# ATSAME54N20A register map
Vendor: Microchip Technology; Series: SAME54; File version: 0
CPU: CM4 r0p1, little endian, MPU, FPU, 3 interrupt priority bits, 137 interrupts
Registers are 32-bit, read-write, reset 0x0 unless marked. A register's access mark holds for its fields unless they carry their own. Offsets are from the block's base; [hi:lo] are bit positions; lines under a group give offsets from that group; {n}, {i} and the like mark numbered series; 'fields as' and 'values as' point back to an identical list.

## SERCOM0 — Serial Communication Interface
Base 0x40003000; register names take the prefix SERCOM_
Same registers: SERCOM1 0x40003400, SERCOM2 0x41012000, SERCOM3 0x41014000, SERCOM4 0x43000000, SERCOM5 0x43000400, SERCOM6 0x43000800, SERCOM7 0x43000C00
0x00 I2CM group — I2C Master Mode
  0x00 CTRLA — I2CM Control A
    [30] LOWTOUTEN — SCL Low Timeout Enable
    [29:28] INACTOUT — Inactive Time-Out
      0=DISABLE (Disabled); 1=55US (5-6 SCL Time-Out(50-60us)); 2=105US (10-11 SCL Time-Out(100-110us)); 3=205US (20-21 SCL Time-Out(200-210us))
    [27] SCLSM — SCL Clock Stretch Mode
    [25:24] SPEED — Transfer Speed
      0=STANDARD_AND_FAST_MODE (Standard Mode(Sm) Upto 100kHz and Fast Mode(Fm) Upto 400kHz); 1=FASTPLUS_MODE (Fast-mode Plus Upto 1MHz); 2=HIGH_SPEED_MODE (High-speed mode Upto 3.4MHz)
    [23] SEXTTOEN — Slave SCL Low Extend Timeout
    [22] MEXTTOEN — Master SCL Low Extend Timeout
    [21:20] SDAHOLD — SDA Hold Time
      0=DISABLE (Disabled); 1=75NS (50-100ns hold time); 2=450NS (300-600ns hold time); 3=600NS (400-800ns hold time)
    [16] PINOUT — Pin Usage
    [7] RUNSTDBY — Run in Standby
    [4:2] MODE — Operating Mode
      0=USART_EXT_CLK (USART with external clock); 1=USART_INT_CLK (USART with internal clock); 2=SPI_SLAVE (SPI in slave operation); 3=SPI_MASTER (SPI in master operation); 4=I2C_SLAVE (I2C slave operation); 5=I2C_MASTER (I2C master operation)
    [1] ENABLE
    [0] SWRST — Software Reset
  0x04 CTRLB — I2CM Control B
    [18] ACKACT — Acknowledge Action
    [17:16] CMD — Command
    [9] QCEN — Quick Command Enable
    [8] SMEN — Smart Mode Enable
  0x08 CTRLC — I2CM Control C
    [24] DATA32B — Data 32 Bit
      0=DATA_TRANS_8BIT (Data transaction from/to DATA register are 8-bit); 1=DATA_TRANS_32BIT (Data transaction from/to DATA register are 32-bit)
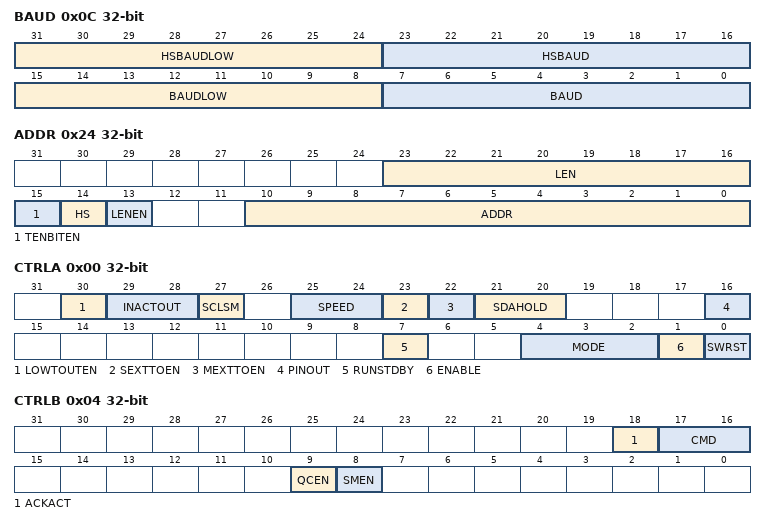
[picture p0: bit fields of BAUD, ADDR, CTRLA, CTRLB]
  0x0C BAUD — I2CM Baud Rate
    [31:24] HSBAUDLOW — High Speed Baud Rate Value Low
    [23:16] HSBAUD — High Speed Baud Rate Value
    [15:8] BAUDLOW — Baud Rate Value Low
    [7:0] BAUD — Baud Rate Value
  0x14 INTENCLR 8-bit write-1-clears — I2CM Interrupt Enable Clear
    [7] ERROR — Combined Error Interrupt Disable
    [1] SB — Slave On Bus Interrupt Disable
    [0] MB — Master On Bus Interrupt Disable
  0x16 INTENSET 8-bit write-1-sets — I2CM Interrupt Enable Set
    [7] ERROR — Combined Error Interrupt Enable
    [1] SB — Slave On Bus Interrupt Enable
    [0] MB — Master On Bus Interrupt Enable
  0x18 INTFLAG 8-bit write-1-clears — I2CM Interrupt Flag Status and Clear
    [7] ERROR — Combined Error Interrupt
    [1] SB — Slave On Bus Interrupt
    [0] MB — Master On Bus Interrupt
  0x1A STATUS 16-bit — I2CM Status
    [10] LENERR — Length Error
    [9] SEXTTOUT — Slave SCL Low Extend Timeout
    [8] MEXTTOUT — Master SCL Low Extend Timeout
    [7] CLKHOLD — Clock Hold
    [6] LOWTOUT — SCL Low Timeout
    [5:4] BUSSTATE
      0=UNKNOWN (The Bus state is unknown to the I2C Host); 1=IDLE (The Bus state is waiting for a transaction to be initialized); 2=OWNER (The I2C Host is the current owner of the bus); 3=BUSY (Some other I2C Host owns the bus)
    [2] RXNACK — Received Not Acknowledge
    [1] ARBLOST — Arbitration Lost
    [0] BUSERR — Bus Error
  0x1C SYNCBUSY ro — I2CM Synchronization Busy
    [2] SYSOP — System Operation Synchronization Busy
    [1] ENABLE — SERCOM Enable Synchronization Busy
    [0] SWRST — Software Reset Synchronization Busy
  0x24 ADDR — I2CM Address
    [23:16] LEN — Length
    [15] TENBITEN — Ten Bit Addressing Enable
    [14] HS — High Speed Mode
    [13] LENEN — Length Enable
    [10:0] ADDR — Address Value
  0x28 DATA — I2CM Data
    [31:0] DATA — Data Value
  0x30 DBGCTRL 8-bit — I2CM Debug Control
    [0] DBGSTOP — Debug Mode
0x00 I2CS group (alternate view of I2CM) — I2C Slave Mode
  0x00 CTRLA — I2CS Control A
    [30] LOWTOUTEN — SCL Low Timeout Enable
    [27] SCLSM — SCL Clock Stretch Mode
    [25:24] SPEED — Transfer Speed
      values as I2CM.CTRLA.SPEED
    [23] SEXTTOEN — Slave SCL Low Extend Timeout
    [21:20] SDAHOLD — SDA Hold Time
      values as I2CM.CTRLA.SDAHOLD
    [16] PINOUT — Pin Usage
    [7] RUNSTDBY — Run during Standby
    [4:2] MODE — Operating Mode
      values as I2CM.CTRLA.MODE
    [1] ENABLE
    [0] SWRST — Software Reset
  0x04 CTRLB — I2CS Control B
    [18] ACKACT — Acknowledge Action
    [17:16] CMD — Command
    [15:14] AMODE — Address Mode
      0=MASK (I2C Address mask); 1=2_ADDRESSES (Two unique Addressess); 2=RANGE (Address Range)
    [10] AACKEN — Automatic Address Acknowledge
    [9] GCMD — PMBus Group Command
    [8] SMEN — Smart Mode Enable
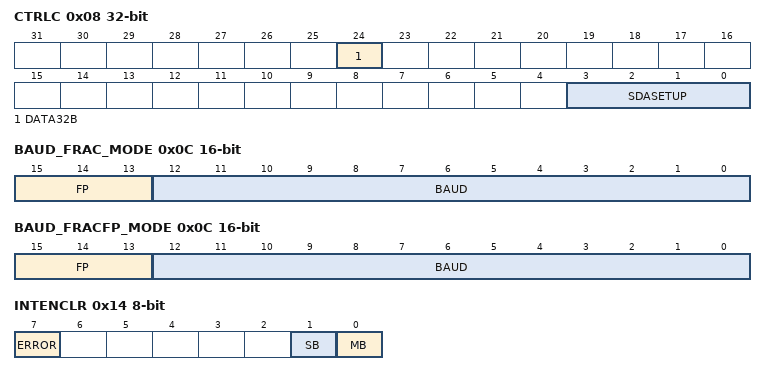
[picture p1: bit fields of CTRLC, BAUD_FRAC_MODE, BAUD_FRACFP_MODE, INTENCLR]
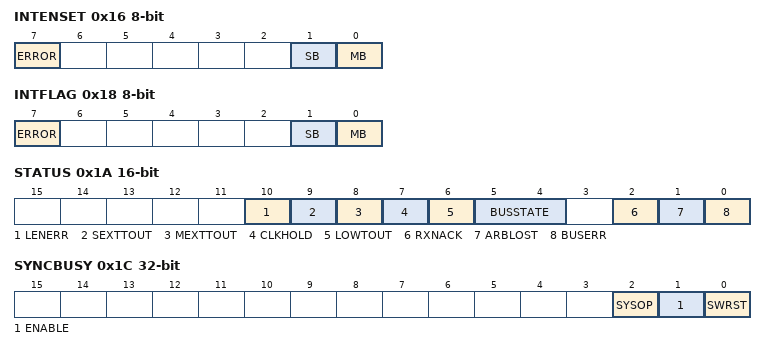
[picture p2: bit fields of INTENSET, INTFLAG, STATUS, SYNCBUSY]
  0x08 CTRLC — I2CS Control C
    [24] DATA32B — Data 32 Bit
      values as I2CM.CTRLC.DATA32B
    [3:0] SDASETUP — SDA Setup Time
  0x14 INTENCLR 8-bit write-1-clears — I2CS Interrupt Enable Clear
    [7] ERROR — Combined Error Interrupt Disable
    [2] DRDY — Data Interrupt Disable
    [1] AMATCH — Address Match Interrupt Disable
    [0] PREC — Stop Received Interrupt Disable
  0x16 INTENSET 8-bit write-1-sets — I2CS Interrupt Enable Set
    [7] ERROR — Combined Error Interrupt Enable
    [2] DRDY — Data Interrupt Enable
    [1] AMATCH — Address Match Interrupt Enable
    [0] PREC — Stop Received Interrupt Enable
  0x18 INTFLAG 8-bit write-1-clears — I2CS Interrupt Flag Status and Clear
    [7] ERROR — Combined Error Interrupt
    [2] DRDY — Data Interrupt
    [1] AMATCH — Address Match Interrupt
    [0] PREC — Stop Received Interrupt
  0x1A STATUS 16-bit — I2CS Status
    [11] LENERR — Transaction Length Error
    [10] HS — High Speed
    [9] SEXTTOUT — Slave SCL Low Extend Timeout
    [7] CLKHOLD — Clock Hold
    [6] LOWTOUT — SCL Low Timeout
    [4] SR — Repeated Start
    [3] DIR — Read/Write Direction
    [2] RXNACK — Received Not Acknowledge
    [1] COLL — Transmit Collision
    [0] BUSERR — Bus Error
  0x1C SYNCBUSY ro — I2CS Synchronization Busy
    [4] LENGTH — Length Synchronization Busy
    [1] ENABLE — SERCOM Enable Synchronization Busy
    [0] SWRST — Software Reset Synchronization Busy
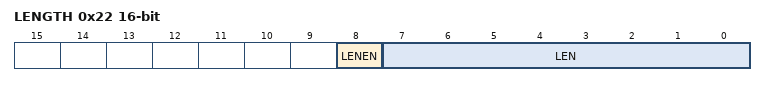
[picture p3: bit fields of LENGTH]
  0x22 LENGTH 16-bit — I2CS Length
    [8] LENEN — Data Length Enable
    [7:0] LEN — Data Length
  0x24 ADDR — I2CS Address
    [26:17] ADDRMASK — Address Mask
    [15] TENBITEN — Ten Bit Addressing Enable
    [10:1] ADDR — Address Value
    [0] GENCEN — General Call Address Enable
  0x28 DATA — I2CS Data
    [31:0] DATA — Data Value
0x00 SPIS group (alternate view of I2CM) — SPI Slave Mode
  0x00 CTRLA — SPIS Control A
    [30] DORD — Data Order
      0=MSB (MSB is transferred first); 1=LSB (LSB is transferred first)
    [29] CPOL — Clock Polarity
      0=IDLE_LOW (SCK is low when idle); 1=IDLE_HIGH (SCK is high when idle)
    [28] CPHA — Clock Phase
      0=LEADING_EDGE (The data is sampled on a leading SCK edge and changed on a trailing SCK edge); 1=TRAILING_EDGE (The data is sampled on a trailing SCK edge and changed on a leading SCK edge)
    [27:24] FORM — Frame Format
      0=SPI_FRAME; 2=SPI_FRAME_WITH_ADDR
    [21:20] DIPO — Data In Pinout
      {v}=PAD{v} (SERCOM PAD[{v}] is used as data input) (v=0..3)
    [17:16] DOPO — Data Out Pinout
      0=PAD0 (DO on PAD[0], SCK on PAD[1] and SS on PAD[2]); 2=PAD2 (DO on PAD[3], SCK on PAD[1] and SS on PAD[2])
    [8] IBON — Immediate Buffer Overflow Notification
    [7] RUNSTDBY — Run during Standby
    [4:2] MODE — Operating Mode
      values as I2CM.CTRLA.MODE
    [1] ENABLE
    [0] SWRST — Software Reset
  0x04 CTRLB — SPIS Control B
    [17] RXEN — Receiver Enable
    [15:14] AMODE — Address Mode
      0=MASK (SPI Address mask); 1=2_ADDRESSES (Two unique Addressess); 2=RANGE (Address Range)
    [13] MSSEN — Master Slave Select Enable
    [9] SSDE — Slave Select Low Detect Enable
    [6] PLOADEN — Data Preload Enable
    [2:0] CHSIZE — Character Size
      0=8_BIT (8 bits); 1=9_BIT (9 bits)
  0x08 CTRLC — SPIS Control C
    [24] DATA32B — Data 32 Bit
      0=DATA_TRANS_8BIT (Transaction from and to DATA register are 8-bit); 1=DATA_TRANS_32BIT (Transaction from and to DATA register are 32-bit)
    [5:0] ICSPACE — Inter-Character Spacing
  0x0C BAUD 8-bit — SPIS Baud Rate
    [7:0] BAUD — Baud Rate Value
  0x14 INTENCLR 8-bit write-1-clears — SPIS Interrupt Enable Clear
    [7] ERROR — Combined Error Interrupt Disable
    [3] SSL — Slave Select Low Interrupt Disable
    [2] RXC — Receive Complete Interrupt Disable
    [1] TXC — Transmit Complete Interrupt Disable
    [0] DRE — Data Register Empty Interrupt Disable
  0x16 INTENSET 8-bit write-1-sets — SPIS Interrupt Enable Set
    [7] ERROR — Combined Error Interrupt Enable
    [3] SSL — Slave Select Low Interrupt Enable
    [2] RXC — Receive Complete Interrupt Enable
    [1] TXC — Transmit Complete Interrupt Enable
    [0] DRE — Data Register Empty Interrupt Enable
  0x18 INTFLAG 8-bit write-1-clears — SPIS Interrupt Flag Status and Clear
    [7] ERROR — Combined Error Interrupt
    [3] SSL — Slave Select Low Interrupt Flag
    [2] RXC — Receive Complete Interrupt
    [1] TXC — Transmit Complete Interrupt
    [0] DRE — Data Register Empty Interrupt
  0x1A STATUS 16-bit — SPIS Status
    [11] LENERR — Transaction Length Error
    [2] BUFOVF — Buffer Overflow
  0x1C SYNCBUSY ro — SPIS Synchronization Busy
    [4] LENGTH — LENGTH Synchronization Busy
    [2] CTRLB — CTRLB Synchronization Busy
    [1] ENABLE — SERCOM Enable Synchronization Busy
    [0] SWRST — Software Reset Synchronization Busy
  0x22 LENGTH 16-bit — SPIS Length
    [8] LENEN — Data Length Enable
    [7:0] LEN — Data Length
  0x24 ADDR — SPIS Address
    [23:16] ADDRMASK — Address Mask
    [7:0] ADDR — Address Value
  0x28 DATA — SPIS Data
    [31:0] DATA — Data Value
  0x30 DBGCTRL 8-bit — SPIS Debug Control
    [0] DBGSTOP — Debug Mode
0x00 SPIM group (alternate view of I2CM) — SPI Master Mode
  0x00 CTRLA — SPIM Control A
    fields as SPIS.CTRLA
  0x04 CTRLB — SPIM Control B
    fields as SPIS.CTRLB
  0x08 CTRLC — SPIM Control C
    fields as SPIS.CTRLC
  0x0C BAUD 8-bit — SPIM Baud Rate
    [7:0] BAUD — Baud Rate Value
  0x14 INTENCLR 8-bit write-1-clears — SPIM Interrupt Enable Clear
    fields as SPIS.INTENCLR
  0x16 INTENSET 8-bit write-1-sets — SPIM Interrupt Enable Set
    fields as SPIS.INTENSET
  0x18 INTFLAG 8-bit write-1-clears — SPIM Interrupt Flag Status and Clear
    fields as SPIS.INTFLAG
  0x1A STATUS 16-bit — SPIM Status
    fields as SPIS.STATUS
  0x1C SYNCBUSY ro — SPIM Synchronization Busy
    fields as SPIS.SYNCBUSY
  0x22 LENGTH 16-bit — SPIM Length
    [8] LENEN — Data Length Enable
    [7:0] LEN — Data Length
  0x24 ADDR — SPIM Address
    [23:16] ADDRMASK — Address Mask
    [7:0] ADDR — Address Value
  0x28 DATA — SPIM Data
    [31:0] DATA — Data Value
  0x30 DBGCTRL 8-bit — SPIM Debug Control
    [0] DBGSTOP — Debug Mode
0x00 USART_EXT group (alternate view of I2CM) — USART EXTERNAL CLOCK Mode
  0x00 CTRLA — USART_EXT Control A
    [30] DORD — Data Order
      0=MSB (MSB is transmitted first); 1=LSB (LSB is transmitted first)
    [29] CPOL — Clock Polarity
      0=IDLE_LOW (TxD Change:- Rising XCK edge, RxD Sample:- Falling XCK edge); 1=IDLE_HIGH (TxD Change:- Falling XCK edge, RxD Sample:- Rising XCK edge)
    [28] CMODE — Communication Mode
      0=ASYNC (Asynchronous Communication); 1=SYNC (Synchronous Communication)
    [27:24] FORM — Frame Format
      0=USART_FRAME_NO_PARITY; 1=USART_FRAME_WITH_PARITY; 2=USART_FRAME_LIN_MASTER_MODE (LIN Master - Break and sync generation); 4=USART_FRAME_AUTO_BAUD_NO_PARITY (Auto-baud (LIN Slave) - break detection and auto-baud); 5=USART_FRAME_AUTO_BAUD_WITH_PARITY (Auto-baud - break detection and auto-baud with parity); 7=USART_FRAME_ISO_7816 (ISO 7816)
    [23:22] SAMPA — Sample Adjustment
      0=ADJ0 (16x Over-sampling = 7-8-9; 8x Over-sampling = 3-4-5); 1=ADJ1 (16x Over-sampling = 9-10-11; 8x Over-sampling = 4-5-6); 2=ADJ2 (16x Over-sampling = 11-12-13; 8x Over-sampling = 5-6-7); 3=ADJ3 (16x Over-sampling = 13-14-15; 8x Over-sampling = 6-7-8)
    [21:20] RXPO — Receive Data Pinout
      {v}=PAD{v} (SERCOM PAD[{v}] is used for data reception) (v=0..3)
    [17:16] TXPO — Transmit Data Pinout
      0=PAD0 (PAD[0] = TxD; PAD[1] = XCK); 2=PAD2 (PAD[0] = TxD; PAD[2] = RTS; PAD[3] = CTS); 3=PAD3 (PAD[0] = TxD; PAD[1] = XCK; PAD[2] = TE)
    [15:13] SAMPR — Sample
      0=16X_ARITHMETIC (16x over-sampling using arithmetic baudrate generation); 1=16X_FRACTIONAL (16x over-sampling using fractional baudrate generation); 2=8X_ARITHMETIC (8x over-sampling using arithmetic baudrate generation); 3=8X_FRACTIONAL (8x over-sampling using fractional baudrate generation); 4=3X_ARITHMETIC (3x over-sampling using arithmetic baudrate generation)
    [10] RXINV — Receive Data Invert
    [9] TXINV — Transmit Data Invert
    [8] IBON — Immediate Buffer Overflow Notification
    [7] RUNSTDBY — Run during Standby
    [4:2] MODE — Operating Mode
      values as I2CM.CTRLA.MODE
    [1] ENABLE
    [0] SWRST — Software Reset
  0x04 CTRLB — USART_EXT Control B
    [25:24] LINCMD — LIN Command
      0=NONE (Normal USART transmission); 1=SOFTWARE_CONTROL_TRANSMIT_CMD (Break field is transmitted when DATA is written); 2=AUTO_TRANSMIT_CMD (Break, sync and identifier are automatically transmitted when DATA is written with the identifier)
    [17] RXEN — Receiver Enable
    [16] TXEN — Transmitter Enable
    [13] PMODE — Parity Mode
      0=EVEN (Even Parity); 1=ODD (Odd Parity)
    [10] ENC — Encoding Format
    [9] SFDE — Start of Frame Detection Enable
    [8] COLDEN — Collision Detection Enable
    [6] SBMODE — Stop Bit Mode
      0=1_BIT (One Stop Bit); 1=2_BIT (Two Stop Bits)
    [2:0] CHSIZE — Character Size
      0=8_BIT (8 Bits); 1=9_BIT (9 Bits); 5=5_BIT (5 Bits); 6=6_BIT (6 Bits); 7=7_BIT (7 Bits)
  0x08 CTRLC — USART_EXT Control C
    [25:24] DATA32B — Data 32 Bit
      0=DATA_READ_WRITE_CHSIZE (Data reads and writes according CTRLB.CHSIZE); 1=DATA_READ_CHSIZE_WRITE_32BIT (Data reads according CTRLB.CHSIZE and writes according 32-bit extension); 2=DATA_READ_32BIT_WRITE_CHSIZE (Data reads according 32-bit extension and writes according CTRLB.CHSIZE); 3=DATA_READ_WRITE_32BIT (Data reads and writes according 32-bit extension)
    [22:20] MAXITER — Maximum Iterations
    [17] DSNACK — Disable Successive NACK
    [16] INACK — Inhibit Not Acknowledge
    [11:10] HDRDLY — LIN Master Header Delay
      0=DELAY0 (Delay between break and sync transmission is 1 bit time; Delay between sync and ID transmission is 1 bit time); 1=DELAY1 (Delay between break and sync transmission is 4 bit time; Delay between sync and ID transmission is 4 bit time); 2=DELAY2 (Delay between break and sync transmission is 8 bit time; Delay between sync and ID transmission is 4 bit time); 3=DELAY3 (Delay between break and sync transmission is 14 bit time; Delay between sync and ID transmission is 4 bit time)
    [9:8] BRKLEN — LIN Master Break Length
      0=13_BIT (Break field transmission is 13 bit times); 1=17_BIT (Break field transmission is 17 bit times); 2=21_BIT (Break field transmission is 21 bit times); 3=26_BIT (Break field transmission is 26 bit times)
    [2:0] GTIME — Guard Time
  0x0C BAUD 16-bit — USART_EXT Baud Rate
    [15:0] BAUD — Baud Rate Value
  0x0C BAUD_FRAC_MODE 16-bit (alternate view of BAUD) — USART_EXT Baud Rate
    [15:13] FP — Fractional Part
    [12:0] BAUD — Baud Rate Value
  0x0C BAUD_FRACFP_MODE 16-bit (alternate view of BAUD) — USART_EXT Baud Rate
    [15:13] FP — Fractional Part
    [12:0] BAUD — Baud Rate Value
  0x0C BAUD_USARTFP_MODE 16-bit (alternate view of BAUD) — USART_EXT Baud Rate
    [15:0] BAUD — Baud Rate Value
  0x0E RXPL 8-bit — USART_EXT Receive Pulse Length
    [7:0] RXPL — Receive Pulse Length
  0x14 INTENCLR 8-bit write-1-clears — USART_EXT Interrupt Enable Clear
    [7] ERROR — Combined Error Interrupt Disable
    [5] RXBRK — Break Received Interrupt Disable
    [4] CTSIC — Clear To Send Input Change Interrupt Disable
    [3] RXS — Receive Start Interrupt Disable
    [2] RXC — Receive Complete Interrupt Disable
    [1] TXC — Transmit Complete Interrupt Disable
    [0] DRE — Data Register Empty Interrupt Disable
  0x16 INTENSET 8-bit write-1-sets — USART_EXT Interrupt Enable Set
    [7] ERROR — Combined Error Interrupt Enable
    [5] RXBRK — Break Received Interrupt Enable
    [4] CTSIC — Clear To Send Input Change Interrupt Enable
    [3] RXS — Receive Start Interrupt Enable
    [2] RXC — Receive Complete Interrupt Enable
    [1] TXC — Transmit Complete Interrupt Enable
    [0] DRE — Data Register Empty Interrupt Enable
  0x18 INTFLAG 8-bit write-1-clears — USART_EXT Interrupt Flag Status and Clear
    [7] ERROR — Combined Error Interrupt
    [5] RXBRK — Break Received Interrupt
    [4] CTSIC — Clear To Send Input Change Interrupt
    [3] RXS — Receive Start Interrupt
    [2] RXC — Receive Complete Interrupt
    [1] TXC — Transmit Complete Interrupt
    [0] DRE — Data Register Empty Interrupt
  0x1A STATUS 16-bit — USART_EXT Status
    [7] ITER — Maximum Number of Repetitions Reached
    [6] TXE — Transmitter Empty
    [5] COLL — Collision Detected
    [4] ISF — Inconsistent Sync Field
    [3] CTS — Clear To Send
    [2] BUFOVF — Buffer Overflow
    [1] FERR — Frame Error
    [0] PERR — Parity Error
  0x1C SYNCBUSY ro — USART_EXT Synchronization Busy
    [4] LENGTH — LENGTH Synchronization Busy
    [3] RXERRCNT — RXERRCNT Synchronization Busy
    [2] CTRLB — CTRLB Synchronization Busy
    [1] ENABLE — SERCOM Enable Synchronization Busy
    [0] SWRST — Software Reset Synchronization Busy
  0x20 RXERRCNT 8-bit ro — USART_EXT Receive Error Count
    [7:0] RXERRCNT — Receive Error Count
  0x22 LENGTH 16-bit — USART_EXT Length
    [9:8] LENEN — Data Length Enable
    [7:0] LEN — Data Length
  0x28 DATA — USART_EXT Data
    [31:0] DATA — Data Value
  0x30 DBGCTRL 8-bit — USART_EXT Debug Control
    [0] DBGSTOP — Debug Mode
0x00 USART_INT group (alternate view of I2CM) — USART INTERNAL CLOCK Mode
  0x00 CTRLA — USART_INT Control A
    fields as USART_EXT.CTRLA
  0x04 CTRLB — USART_INT Control B
    fields as USART_EXT.CTRLB
  0x08 CTRLC — USART_INT Control C
    fields as USART_EXT.CTRLC
  0x0C BAUD 16-bit — USART_INT Baud Rate
    [15:0] BAUD — Baud Rate Value
  0x0C BAUD_FRAC_MODE 16-bit (alternate view of BAUD) — USART_INT Baud Rate
    [15:13] FP — Fractional Part
    [12:0] BAUD — Baud Rate Value
  0x0C BAUD_FRACFP_MODE 16-bit (alternate view of BAUD) — USART_INT Baud Rate
    [15:13] FP — Fractional Part
    [12:0] BAUD — Baud Rate Value
  0x0C BAUD_USARTFP_MODE 16-bit (alternate view of BAUD) — USART_INT Baud Rate
    [15:0] BAUD — Baud Rate Value
  0x0E RXPL 8-bit — USART_INT Receive Pulse Length
    [7:0] RXPL — Receive Pulse Length
  0x14 INTENCLR 8-bit write-1-clears — USART_INT Interrupt Enable Clear
    fields as USART_EXT.INTENCLR
  0x16 INTENSET 8-bit write-1-sets — USART_INT Interrupt Enable Set
    fields as USART_EXT.INTENSET
  0x18 INTFLAG 8-bit write-1-clears — USART_INT Interrupt Flag Status and Clear
    fields as USART_EXT.INTFLAG
  0x1A STATUS 16-bit — USART_INT Status
    fields as USART_EXT.STATUS
  0x1C SYNCBUSY ro — USART_INT Synchronization Busy
    fields as USART_EXT.SYNCBUSY
  0x20 RXERRCNT 8-bit ro — USART_INT Receive Error Count
    [7:0] RXERRCNT — Receive Error Count
  0x22 LENGTH 16-bit — USART_INT Length
    [9:8] LENEN — Data Length Enable
    [7:0] LEN — Data Length
  0x28 DATA — USART_INT Data
    [31:0] DATA — Data Value
  0x30 DBGCTRL 8-bit — USART_INT Debug Control
    [0] DBGSTOP — Debug Mode

## Notices in the file
Copyright (c) 2026 Microchip Technology Inc.
SPDX-License-Identifier: Apache-2.0
Licensed under the Apache License, Version 2.0 (the "License");
you may not use this file except in compliance with the License.
You may obtain a copy of the License at
http://www.apache.org/licenses/LICENSE-2.0
Unless required by applicable law or agreed to in writing, software
distributed under the License is distributed on an "AS IS" BASIS,
WITHOUT WARRANTIES OR CONDITIONS OF ANY KIND, either express or implied.
See the License for the specific language governing permissions and
limitations under the License.
